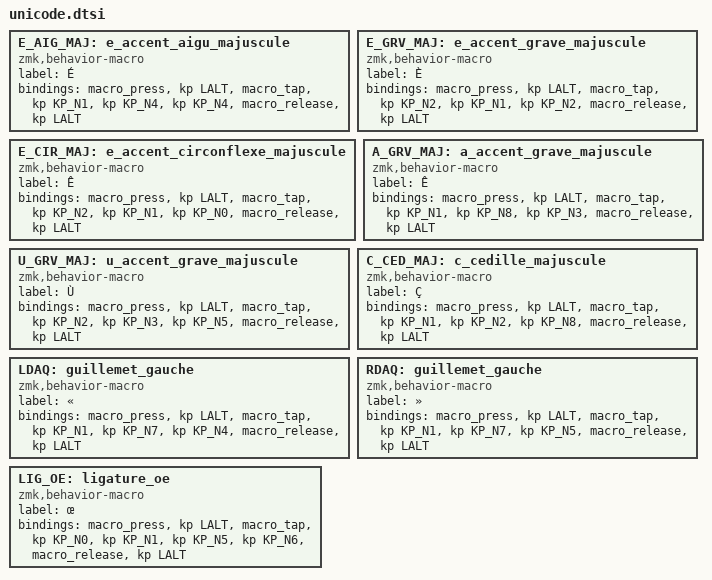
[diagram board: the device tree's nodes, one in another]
E_AIG_MAJ: e_accent_aigu_majuscule {
	compatible = "zmk,behavior-macro";
	label = "É";
	#binding-cells = <0>;
	bindings = <&macro_press   	 &kp LALT>
			 , <&macro_tap     	 &kp KP_N1 &kp KP_N4 &kp KP_N4>
			 , <&macro_release 	 &kp LALT>
	;
};

E_GRV_MAJ: e_accent_grave_majuscule {
	compatible = "zmk,behavior-macro";
	label = "È";
	#binding-cells = <0>;
	bindings = <&macro_press   	 &kp LALT>
			 , <&macro_tap     	 &kp KP_N2 &kp KP_N1 &kp KP_N2>
			 , <&macro_release 	 &kp LALT>
	;
};

E_CIR_MAJ: e_accent_circonflexe_majuscule {
	compatible = "zmk,behavior-macro";
	label = "Ê";
	#binding-cells = <0>;
	bindings = <&macro_press   	 &kp LALT>
			 , <&macro_tap     	 &kp KP_N2 &kp KP_N1 &kp KP_N0>
			 , <&macro_release 	 &kp LALT>
	;
};

A_GRV_MAJ: a_accent_grave_majuscule {
	compatible = "zmk,behavior-macro";
	label = "Ê";
	#binding-cells = <0>;
	bindings = <&macro_press   	 &kp LALT>
			 , <&macro_tap     	 &kp KP_N1 &kp KP_N8 &kp KP_N3>
			 , <&macro_release 	 &kp LALT>
	;
};

U_GRV_MAJ: u_accent_grave_majuscule {
	compatible = "zmk,behavior-macro";
	label = "Ù";
	#binding-cells = <0>;
	bindings = <&macro_press   	 &kp LALT>
			 , <&macro_tap     	 &kp KP_N2 &kp KP_N3 &kp KP_N5>
			 , <&macro_release 	 &kp LALT>
	;
};

C_CED_MAJ: c_cedille_majuscule {
	compatible = "zmk,behavior-macro";
	label = "Ç";
	#binding-cells = <0>;
	bindings = <&macro_press   	 &kp LALT>
			 , <&macro_tap     	 &kp KP_N1 &kp KP_N2 &kp KP_N8>
			 , <&macro_release 	 &kp LALT>
	;
};

LDAQ: guillemet_gauche {
	compatible = "zmk,behavior-macro";
	label = "«";
	#binding-cells = <0>;
	bindings = <&macro_press   	 &kp LALT>
			 , <&macro_tap     	 &kp KP_N1 &kp KP_N7 &kp KP_N4>
			 , <&macro_release 	 &kp LALT>
	;
};

RDAQ: guillemet_gauche {
	compatible = "zmk,behavior-macro";
	label = "»";
	#binding-cells = <0>;
	bindings = <&macro_press   	 &kp LALT>
			 , <&macro_tap     	 &kp KP_N1 &kp KP_N7 &kp KP_N5>
			 , <&macro_release 	 &kp LALT>
	;
};

LIG_OE: ligature_oe {
	compatible = "zmk,behavior-macro";
	label = "œ";
	#binding-cells = <0>;
	bindings = <&macro_press   	 &kp LALT>
			 , <&macro_tap     	 &kp KP_N0 &kp KP_N1 &kp KP_N5 &kp KP_N6>
			 , <&macro_release 	 &kp LALT>
	;
};

